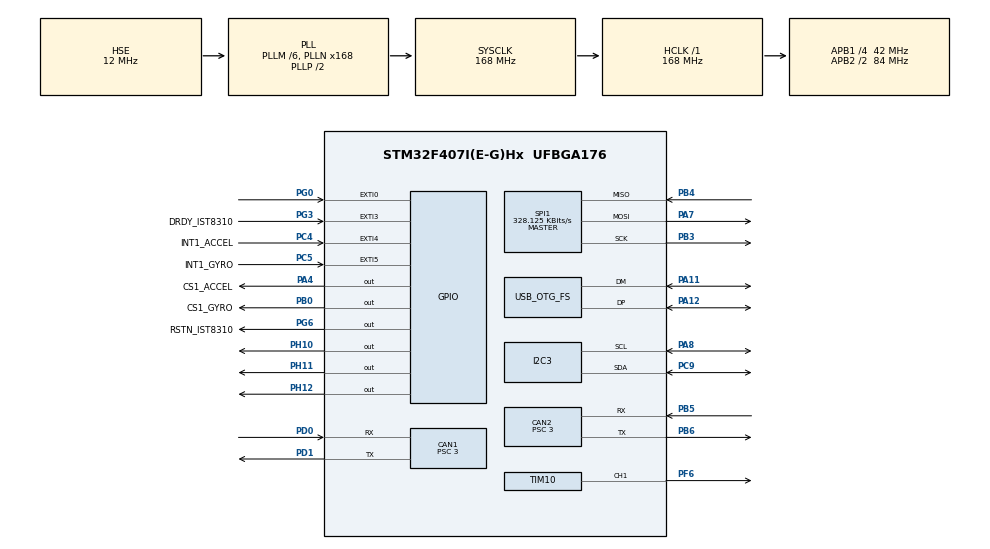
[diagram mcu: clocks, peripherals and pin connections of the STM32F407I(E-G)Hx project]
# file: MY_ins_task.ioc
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CAN1.BS1=CAN_BS1_10TQ
CAN1.BS2=CAN_BS2_3TQ
CAN1.CalculateBaudRate=1000000
CAN1.CalculateTimeBit=1000
CAN1.CalculateTimeQuantum=71.42857142857143
CAN1.Prescaler=3
CAN2.BS1=CAN_BS1_10TQ
CAN2.BS2=CAN_BS2_3TQ
CAN2.CalculateBaudRate=1000000
CAN2.CalculateTimeBit=1000
CAN2.CalculateTimeQuantum=71.42857142857143
CAN2.Prescaler=3
Dma.Request0=SPI1_RX
Dma.Request1=SPI1_TX
Dma.SPI1_RX.0.Direction=DMA_PERIPH_TO_MEMORY
Dma.SPI1_RX.0.FIFOMode=DMA_FIFOMODE_DISABLE
Dma.SPI1_RX.0.Instance=DMA2_Stream2
Dma.SPI1_RX.0.MemDataAlignment=DMA_MDATAALIGN_BYTE
Dma.SPI1_RX.0.MemInc=DMA_MINC_ENABLE
Dma.SPI1_RX.0.Mode=DMA_NORMAL
Dma.SPI1_RX.0.PeriphDataAlignment=DMA_PDATAALIGN_BYTE
Dma.SPI1_RX.0.PeriphInc=DMA_PINC_DISABLE
Dma.SPI1_RX.0.Priority=DMA_PRIORITY_VERY_HIGH
Dma.SPI1_TX.1.Direction=DMA_MEMORY_TO_PERIPH
Dma.SPI1_TX.1.FIFOMode=DMA_FIFOMODE_DISABLE
Dma.SPI1_TX.1.Instance=DMA2_Stream3
Dma.SPI1_TX.1.MemDataAlignment=DMA_MDATAALIGN_BYTE
Dma.SPI1_TX.1.MemInc=DMA_MINC_ENABLE
Dma.SPI1_TX.1.Mode=DMA_NORMAL
Dma.SPI1_TX.1.PeriphDataAlignment=DMA_PDATAALIGN_BYTE
Dma.SPI1_TX.1.PeriphInc=DMA_PINC_DISABLE
Dma.SPI1_TX.1.Priority=DMA_PRIORITY_HIGH
FREERTOS.INCLUDE_eTaskGetState=1
FREERTOS.INCLUDE_pcTaskGetTaskName=1
FREERTOS.INCLUDE_uxTaskGetStackHighWaterMark=1
FREERTOS.INCLUDE_uxTaskGetStackHighWaterMark2=1
FREERTOS.INCLUDE_vTaskCleanUpResources=1
FREERTOS.INCLUDE_vTaskDelayUntil=1
FREERTOS.INCLUDE_xQueueGetMutexHolder=1
FREERTOS.INCLUDE_xSemaphoreGetMutexHolder=1
FREERTOS.INCLUDE_xTaskAbortDelay=1
FREERTOS.INCLUDE_xTaskGetCurrentTaskHandle=1
FREERTOS.INCLUDE_xTaskGetHandle=1
FREERTOS.Tasks01=gimbal_task,0,256,my_gimbal_task,As weak,NULL,Dynamic,NULL,NULL;my_ins_task,3,1024,INS_task,As weak,NULL,Dynamic,NULL,NULL;My_usb,2,1024,my_usb,As weak,NULL,Dynamic,NULL,NULL
I2C3.I2C_Mode=I2C_Fast
Mcu.Family=STM32F4
Mcu.Name=STM32F407I(E-G)Hx
Mcu.Package=UFBGA176
NVIC.CAN1_RX0_IRQn=true\:5\:0\:false\:false\:true\:true\:true\:true\:true
NVIC.CAN2_RX0_IRQn=true\:5\:0\:false\:false\:true\:true\:true\:true\:true
NVIC.DMA2_Stream2_IRQn=true\:5\:0\:false\:false\:true\:true\:false\:true\:true
NVIC.DMA2_Stream3_IRQn=true\:5\:0\:false\:false\:true\:true\:false\:true\:true
NVIC.EXTI0_IRQn=true\:6\:0\:true\:false\:true\:true\:true\:true\:true
NVIC.EXTI3_IRQn=true\:5\:0\:true\:false\:true\:true\:true\:true\:true
NVIC.EXTI4_IRQn=true\:5\:0\:true\:false\:true\:true\:true\:true\:true
NVIC.EXTI9_5_IRQn=true\:5\:0\:true\:false\:true\:true\:true\:true\:true
NVIC.OTG_FS_IRQn=true\:5\:0\:false\:false\:true\:true\:false\:true\:true
NVIC.PriorityGroup=NVIC_PRIORITYGROUP_4
NVIC.TIM2_IRQn=true\:15\:0\:false\:false\:true\:false\:false\:true\:true
NVIC.TimeBase=TIM2_IRQn
NVIC.TimeBaseIP=TIM2
PA11.Mode=Device_Only
PA11.Signal=USB_OTG_FS_DM
PA12.Mode=Device_Only
PA12.Signal=USB_OTG_FS_DP
PA13.Mode=Serial_Wire
PA13.Signal=SYS_JTMS-SWDIO
PA14.Mode=Serial_Wire
PA14.Signal=SYS_JTCK-SWCLK
PA4.GPIO_Label=CS1_ACCEL
PA4.GPIO_PuPd=GPIO_PULLUP
PA4.GPIO_Speed=GPIO_SPEED_FREQ_HIGH
PA4.PinState=GPIO_PIN_SET
PA4.Signal=GPIO_Output
PA7.GPIO_PuPd=GPIO_PULLUP
PA7.Mode=Full_Duplex_Master
PA7.Signal=SPI1_MOSI
PA8.Mode=I2C
PA8.Signal=I2C3_SCL
PB0.GPIO_Label=CS1_GYRO
PB0.GPIO_PuPd=GPIO_PULLUP
PB0.GPIO_Speed=GPIO_SPEED_FREQ_HIGH
PB0.PinState=GPIO_PIN_SET
PB0.Signal=GPIO_Output
PB3.GPIO_PuPd=GPIO_PULLUP
PB3.Mode=Full_Duplex_Master
PB3.Signal=SPI1_SCK
PB4.GPIO_PuPd=GPIO_PULLUP
PB4.Mode=Full_Duplex_Master
PB4.Signal=SPI1_MISO
PB5.Mode=CAN_Activate
PB5.Signal=CAN2_RX
PB6.Mode=CAN_Activate
PB6.Signal=CAN2_TX
PC4.GPIO_Label=INT1_ACCEL
PC4.GPIO_ModeDefaultEXTI=GPIO_MODE_IT_FALLING
PC4.GPIO_PuPd=GPIO_PULLUP
PC4.Signal=GPXTI4
PC5.GPIO_Label=INT1_GYRO
PC5.GPIO_ModeDefaultEXTI=GPIO_MODE_IT_FALLING
PC5.GPIO_PuPd=GPIO_PULLUP
PC5.Signal=GPXTI5
PC9.Mode=I2C
PC9.Signal=I2C3_SDA
PD0.Mode=CAN_Activate
PD0.Signal=CAN1_RX
PD1.Mode=CAN_Activate
PD1.Signal=CAN1_TX
PF6.Signal=S_TIM10_CH1
PG0.GPIO_ModeDefaultEXTI=GPIO_MODE_IT_FALLING
PG0.GPIO_PuPd=GPIO_PULLUP
PG0.Signal=GPXTI0
PG3.GPIO_Label=DRDY_IST8310
PG3.GPIO_ModeDefaultEXTI=GPIO_MODE_IT_FALLING
PG3.GPIO_PuPd=GPIO_PULLUP
PG3.Signal=GPXTI3
PG6.GPIO_Label=RSTN_IST8310
PG6.GPIO_PuPd=GPIO_PULLUP
PG6.GPIO_Speed=GPIO_SPEED_FREQ_MEDIUM
PG6.PinState=GPIO_PIN_SET
PG6.Signal=GPIO_Output
PH0-OSC_IN.Mode=HSE-External-Oscillator
PH0-OSC_IN.Signal=RCC_OSC_IN
PH1-OSC_OUT.Mode=HSE-External-Oscillator
PH1-OSC_OUT.Signal=RCC_OSC_OUT
PH10.Signal=GPIO_Output
PH11.Signal=GPIO_Output
PH12.Signal=GPIO_Output
ProjectManager.HeapSize=0x200
ProjectManager.StackSize=0x400
ProjectManager.TargetToolchain=MDK-ARM V5.32
RCC.48MHZClocksFreq_Value=48000000
RCC.AHBFreq_Value=168000000
RCC.APB1CLKDivider=RCC_HCLK_DIV4
RCC.APB1Freq_Value=42000000
RCC.APB1TimFreq_Value=84000000
RCC.APB2CLKDivider=RCC_HCLK_DIV2
RCC.APB2Freq_Value=84000000
RCC.APB2TimFreq_Value=168000000
RCC.CortexFreq_Value=168000000
RCC.HCLKFreq_Value=168000000
RCC.HSE_VALUE=12000000
RCC.HSI_VALUE=16000000
RCC.LSE_VALUE=32768
RCC.PLLM=6
RCC.PLLN=168
RCC.PLLQ=7
RCC.SYSCLKFreq_VALUE=168000000
RCC.SYSCLKSource=RCC_SYSCLKSOURCE_PLLCLK
RCC.VCOOutputFreq_Value=336000000
SH.S_TIM10_CH1.0=TIM10_CH1,PWM Generation1 CH1
SPI1.BaudRatePrescaler=SPI_BAUDRATEPRESCALER_256
SPI1.CLKPhase=SPI_PHASE_2EDGE
SPI1.CLKPolarity=SPI_POLARITY_HIGH
SPI1.CalculateBaudRate=328.125 KBits/s
SPI1.Direction=SPI_DIRECTION_2LINES
SPI1.Mode=SPI_MODE_MASTER
SPI1.VirtualType=VM_MASTER
TIM10.Channel=TIM_CHANNEL_1
USB_DEVICE.CLASS_NAME_FS=CDC
USB_DEVICE.MANUFACTURER_STRING-CDC_FS=RM
USB_DEVICE.PID_CDC_FS=0x514
USB_DEVICE.VID-CDC_FS=0x114
USB_DEVICE.VirtualMode-CDC_FS=Cdc
USB_DEVICE.VirtualModeFS=Cdc_FS
USB_OTG_FS.VirtualMode=Device_Only
VP_FREERTOS_VS_CMSIS_V1.Mode=CMSIS_V1
VP_SYS_VS_tim2.Mode=TIM2
VP_TIM10_VS_ClockSourceINT.Mode=Enable_Timer
VP_USB_DEVICE_VS_USB_DEVICE_CDC_FS.Mode=CDC_FS
board=custom

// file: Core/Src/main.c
/* USER CODE BEGIN Header */
/**
  ******************************************************************************
  * @file           : main.c
  * @brief          : Main program body
  ******************************************************************************
  * @attention
  *
  * Copyright (c) 2026 STMicroelectronics.
  * All rights reserved.
  *
  * This software is licensed under terms that can be found in the LICENSE file
  * in the root directory of this software component.
  * If no LICENSE file comes with this software, it is provided AS-IS.
  *
  ******************************************************************************
  */
/* USER CODE END Header */
#include "main.h"
#include "cmsis_os.h"
#include "can.h"
#include "dma.h"
#include "i2c.h"
#include "spi.h"
#include "tim.h"
#include "usb_device.h"
#include "gpio.h"

/* USER CODE BEGIN Includes */
#include "bsp_delay.h"
#include "bsp_can.h"
#include "bsp_usb.h"
/* USER CODE END Includes */

void SystemClock_Config(void);
void MX_FREERTOS_Init(void);

int main(void)
{

  /* MCU Configuration--------------------------------------------------------*/

  /* Reset of all peripherals, Initializes the Flash interface and the Systick. */
  HAL_Init();

  /* Configure the system clock */
  SystemClock_Config();

  /* Initialize all configured peripherals */
  MX_GPIO_Init();
  MX_DMA_Init();
  MX_I2C3_Init();
  MX_SPI1_Init();
  MX_TIM10_Init();
  MX_CAN1_Init();
  MX_CAN2_Init();
  /* USER CODE BEGIN 2 */
delay_init();
can_filter_init();
usb_init();
  /* USER CODE END 2 */

  /* Call init function for freertos objects (in cmsis_os2.c) */
  MX_FREERTOS_Init();

  /* Start scheduler */
  osKernelStart();

  /* We should never get here as control is now taken by the scheduler */

  /* Infinite loop */
  while (1)
  {

  }
}

void SystemClock_Config(void)
{
  RCC_OscInitTypeDef RCC_OscInitStruct = {0};
  RCC_ClkInitTypeDef RCC_ClkInitStruct = {0};

  /** Configure the main internal regulator output voltage
  */
  __HAL_RCC_PWR_CLK_ENABLE();
  __HAL_PWR_VOLTAGESCALING_CONFIG(PWR_REGULATOR_VOLTAGE_SCALE1);

  /** Initializes the RCC Oscillators according to the specified parameters
  * in the RCC_OscInitTypeDef structure.
  */
  RCC_OscInitStruct.OscillatorType = RCC_OSCILLATORTYPE_HSE;
  RCC_OscInitStruct.HSEState = RCC_HSE_ON;
  RCC_OscInitStruct.PLL.PLLState = RCC_PLL_ON;
  RCC_OscInitStruct.PLL.PLLSource = RCC_PLLSOURCE_HSE;
  RCC_OscInitStruct.PLL.PLLM = 6;
  RCC_OscInitStruct.PLL.PLLN = 168;
  RCC_OscInitStruct.PLL.PLLP = RCC_PLLP_DIV2;
  RCC_OscInitStruct.PLL.PLLQ = 7;
  if (HAL_RCC_OscConfig(&RCC_OscInitStruct) != HAL_OK)
  {
    Error_Handler();
  }

  /** Initializes the CPU, AHB and APB buses clocks
  */
  RCC_ClkInitStruct.ClockType = RCC_CLOCKTYPE_HCLK|RCC_CLOCKTYPE_SYSCLK
                              |RCC_CLOCKTYPE_PCLK1|RCC_CLOCKTYPE_PCLK2;
  RCC_ClkInitStruct.SYSCLKSource = RCC_SYSCLKSOURCE_PLLCLK;
  RCC_ClkInitStruct.AHBCLKDivider = RCC_SYSCLK_DIV1;
  RCC_ClkInitStruct.APB1CLKDivider = RCC_HCLK_DIV4;
  RCC_ClkInitStruct.APB2CLKDivider = RCC_HCLK_DIV2;

  if (HAL_RCC_ClockConfig(&RCC_ClkInitStruct, FLASH_LATENCY_5) != HAL_OK)
  {
    Error_Handler();
  }
}

void HAL_TIM_PeriodElapsedCallback(TIM_HandleTypeDef *htim)
{
  if (htim->Instance == TIM2) {
    HAL_IncTick();
  }
}

void Error_Handler(void)
{
  __disable_irq();
  while (1)
  {
  }
}

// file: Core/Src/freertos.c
/* USER CODE BEGIN Header */
/**
  ******************************************************************************
  * File Name          : freertos.c
  * Description        : Code for freertos applications
  ******************************************************************************
  * @attention
  *
  * Copyright (c) 2026 STMicroelectronics.
  * All rights reserved.
  *
  * This software is licensed under terms that can be found in the LICENSE file
  * in the root directory of this software component.
  * If no LICENSE file comes with this software, it is provided AS-IS.
  *
  ******************************************************************************
  */
/* USER CODE END Header */

#include "FreeRTOS.h"
#include "task.h"
#include "main.h"
#include "cmsis_os.h"

osThreadId gimbal_taskHandle;
osThreadId my_ins_taskHandle;
osThreadId My_usbHandle;

void my_gimbal_task(void const * argument);
void INS_task(void const * argument);
void my_usb(void const * argument);

extern void MX_USB_DEVICE_Init(void);
void MX_FREERTOS_Init(void); /* (MISRA C 2004 rule 8.1) */

/* GetIdleTaskMemory prototype (linked to static allocation support) */
void vApplicationGetIdleTaskMemory( StaticTask_t **ppxIdleTaskTCBBuffer, StackType_t **ppxIdleTaskStackBuffer, uint32_t *pulIdleTaskStackSize );

/* USER CODE BEGIN GET_IDLE_TASK_MEMORY */
static StaticTask_t xIdleTaskTCBBuffer;
static StackType_t xIdleStack[configMINIMAL_STACK_SIZE];

void vApplicationGetIdleTaskMemory( StaticTask_t **ppxIdleTaskTCBBuffer, StackType_t **ppxIdleTaskStackBuffer, uint32_t *pulIdleTaskStackSize )
{
  *ppxIdleTaskTCBBuffer = &xIdleTaskTCBBuffer;
  *ppxIdleTaskStackBuffer = &xIdleStack[0];
  *pulIdleTaskStackSize = configMINIMAL_STACK_SIZE;
  /* place for user code */
}
/* USER CODE END GET_IDLE_TASK_MEMORY */

void MX_FREERTOS_Init(void) {

  /* Create the thread(s) */
  /* definition and creation of gimbal_task */
  osThreadDef(gimbal_task, my_gimbal_task, osPriorityNormal, 0, 256);
  gimbal_taskHandle = osThreadCreate(osThread(gimbal_task), NULL);

  /* definition and creation of my_ins_task */
  osThreadDef(my_ins_task, INS_task, osPriorityRealtime, 0, 1024);
  my_ins_taskHandle = osThreadCreate(osThread(my_ins_task), NULL);

  /* definition and creation of My_usb */
  osThreadDef(My_usb, my_usb, osPriorityHigh, 0, 1024);
  My_usbHandle = osThreadCreate(osThread(My_usb), NULL);

}

__weak void my_gimbal_task(void const * argument)
{
  /* init code for USB_DEVICE */
  MX_USB_DEVICE_Init();
  for(;;)
  {
    osDelay(1);
  }
}

__weak void INS_task(void const * argument)
{
  for(;;)
  {
    osDelay(1);
  }
}

__weak void my_usb(void const * argument)
{
  for(;;)
  {
    osDelay(1);
  }
}
